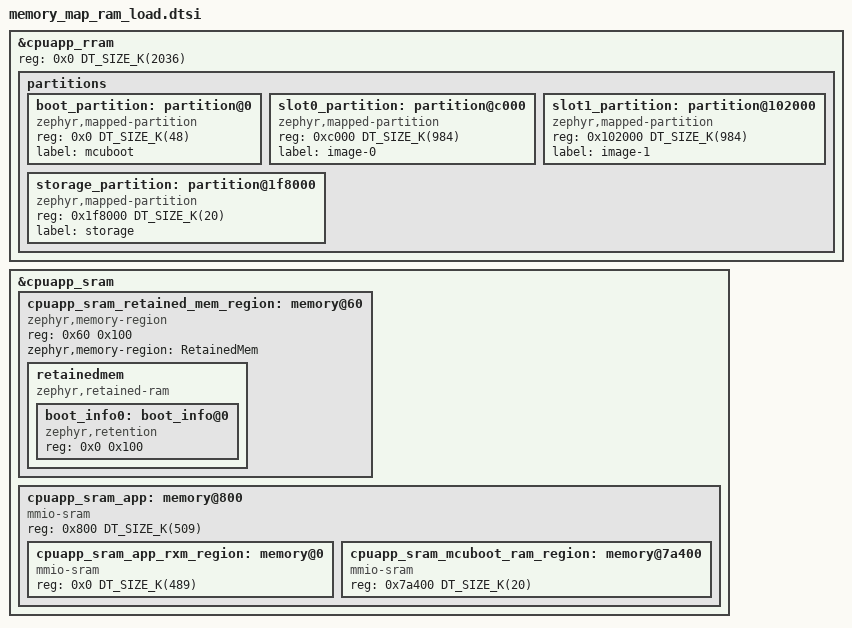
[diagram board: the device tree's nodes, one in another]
/*
 * Copyright (c) 2025 Nordic Semiconductor ASA
 *
 * SPDX-License-Identifier: LicenseRef-Nordic-5-Clause
 */

&cpuapp_rram {
	/* Application does not use cpuflpr core. Assign whole RRAM to cpuapp. */
	reg = <0x0 DT_SIZE_K(2036)>;

	/* Redefine the "partitions" DTS node. */
	/delete-node/ partitions;

	partitions {
		ranges;
		#address-cells = <1>;
		#size-cells = <1>;

		/* Significantly increase the size of the MCUboot partition to make it fit
		 * for the LLVM configuration variant.
		 */
		boot_partition: partition@0 {
			compatible = "zephyr,mapped-partition";
			reg = <0x0 DT_SIZE_K(48)>;
			label = "mcuboot";
		};

		slot0_partition: partition@c000 {
			compatible = "zephyr,mapped-partition";
			reg = <0xc000 DT_SIZE_K(984)>;
			label = "image-0";
		};

		slot1_partition: partition@102000 {
			compatible = "zephyr,mapped-partition";
			reg = <0x102000 DT_SIZE_K(984)>;
			label = "image-1";
		};

		storage_partition: partition@1f8000 {
			compatible = "zephyr,mapped-partition";
			reg = <0x1f8000 DT_SIZE_K(20)>;
			label = "storage";
		};
	};
};

/* Remove the DTS node with the "cpuapp_sram_app" label to redefine the RAM layout.
 * The parent "cpuapp_sram" DTS node is kept, and the "kmu_push_area" DTS node from
 * the SoC devicetree keeps the beginning of the physical RAM reserved for the KMU.
 */
/delete-node/ &cpuapp_sram_app;

&cpuapp_sram {
	/* SRAM region that is shared by both the MCUboot image and the application code.
	 * Currently, it is used to share the image metadata between the bootloader and
	 * the application. This region is retained across reboots only if the
	 * CONFIG_RETAINED_MEM_NRF_RAM_CTRL Kconfig option is enabled.
	 */
	cpuapp_sram_retained_mem_region: memory@60 {
		compatible = "zephyr,memory-region", "mmio-sram";
		reg = <0x60 0x100>;
		zephyr,memory-region = "RetainedMem";
		status = "okay";

		retainedmem {
			compatible = "zephyr,retained-ram";
			#address-cells = <1>;
			#size-cells = <1>;
			status = "okay";

			boot_info0: boot_info@0 {
				compatible = "zephyr,retention";
				reg = <0x0 0x100>;
				status = "okay";
			};
		};
	};

	/* Redefine the "cpuapp_sram_app" DTS node and specify the necessary RAM subregions
	 * that can be used to configure the MCUboot image. The board devicetree assigns this
	 * DTS node to the application image as its chosen SRAM DTS node. Additionally, the
	 * start address of this DTS node must be aligned with 0x800 bytes due to the Zephyr
	 * build system requirements. The build system places the executable ROM section
	 * (code) at the beginning of this region and the RAM section (data) right after
	 * the ROM section.
	 */
	cpuapp_sram_app: memory@800 {
		compatible = "mmio-sram";
		reg = <0x800 DT_SIZE_K(509)>;
		ranges = <0x0 0x800 DT_SIZE_K(509)>;
		#address-cells = <1>;
		#size-cells = <1>;

		/* SRAM region for storing the ROM section (code) and RAM section (data) of
		 * the application image. The RAM section of the application image may also
		 * partially or fully fill the subsequent SRAM region called
		 * "cpuapp_sram_mcuboot_ram_region", but its ROM section must never enter
		 * this region. This ROM section defines the memory space where MCUboot
		 * copies the application image. If this copied data overlaps with the
		 * MCUboot RAM region, MCUboot may encounter runtime errors. It is
		 * recommended to use this DTS node for configuration of the executable
		 * SRAM region in the MCUboot image. Point /chosen/mcuboot,image-ram at
		 * this node in both MCUboot and application images so
		 * CONFIG_BOOT_IMAGE_EXECUTABLE_RAM_START/SIZE default from devicetree.
		 */
		cpuapp_sram_app_rxm_region: memory@0 {
			compatible = "mmio-sram";
			reg = <0x0 DT_SIZE_K(489)>;
			ranges = <0x0 0x0 DT_SIZE_K(489)>;
			#address-cells = <1>;
			#size-cells = <1>;
		};

		/* SRAM region for storing the RAM section (data) of the MCUboot image. The
		 * RAM section of the application image may also partially or fully fill
		 * this region, but the ROM section of the application image must never
		 * enter this region. This ROM section defines the memory space where
		 * MCUboot copies the application image. If this copied data overlaps with
		 * the MCUboot RAM region, MCUboot may encounter runtime errors. This DTS
		 * node must be assigned to the MCUboot image as its chosen SRAM DTS node.
		 */
		cpuapp_sram_mcuboot_ram_region: memory@7a400 {
			compatible = "mmio-sram";
			reg = <0x7a400 DT_SIZE_K(20)>;
			ranges = <0x0 0x7a400 DT_SIZE_K(20)>;
			#address-cells = <1>;
			#size-cells = <1>;
		};
	};
};
